VERSION "2.0"

// ============================================================
// FORMULA PROJECT - CAN Communication
// Steering Wheel ↔ ECU
// ============================================================

NS_ :

BS_:
BU_: SteeringWheel ECU

// ============================================================
// MESSAGE: SteeringWheel_Status (TX from SteeringWheel → ECU)
// ============================================================

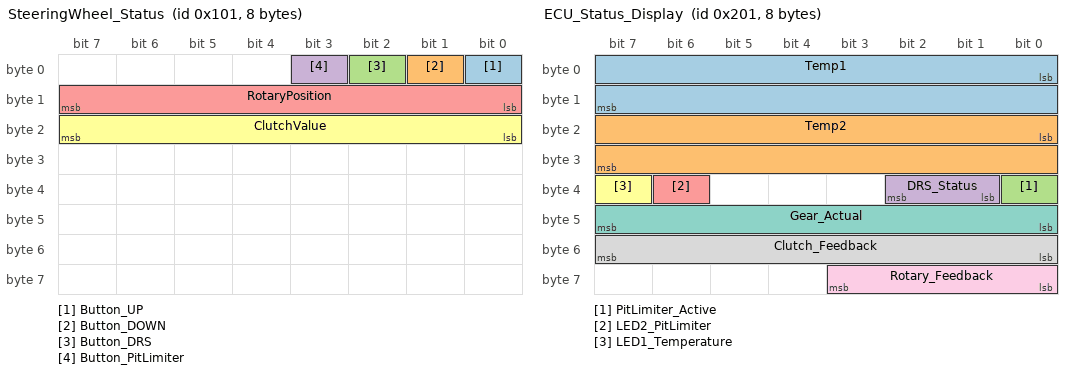
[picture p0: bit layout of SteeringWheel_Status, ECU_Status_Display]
BO_ 257 SteeringWheel_Status: 8 SteeringWheel
 // NOTE: @1+ used for PC simulation (SocketCAN).
 // In target hardware (S32K118 FlexCAN), use @0+.

 SG_ Button_UP :  0|1@1+ (1,0) [0|1] "" ECU
 SG_ Button_DOWN : 1|1@1+ (1,0) [0|1] "" ECU
 SG_ Button_DRS : 2|1@1+ (1,0) [0|1] "" ECU
 SG_ Button_PitLimiter : 3|1@1+ (1,0) [0|1] "" ECU
 SG_ RotaryPosition : 8|8@1+ (1,0) [0|15] ""  ECU
 SG_ ClutchValue : 16|8@1+ (1,0) [0|100] "%"  ECU

// ============================================================
// MESSAGE: ECU_Status_Display (TX from ECU → SteeringWheel)
// ============================================================

BO_ 513 ECU_Status_Display: 8 ECU

 // --- BYTE 0-1 ---
 SG_ Temp1              :  0|16@1+ (0.1,-40) [-40|150] "°C" SteeringWheel

 // --- BYTE 2-3 ---
 SG_ Temp2              : 16|16@1+ (0.1,-40) [-40|150] "°C" SteeringWheel

 // --- BYTE 4 ---
 SG_ PitLimiter_Active  : 32|1@1+ (1,0) [0|1] "" SteeringWheel
 SG_ DRS_Status         : 33|2@1+ (1,0) [0|1] "" SteeringWheel
 SG_ LED2_PitLimiter    : 38|1@1+ (1,0) [0|1] "" SteeringWheel
 SG_ LED1_Temperature   : 39|1@1+ (1,0) [0|1] "" SteeringWheel

 // --- BYTE 5 ---
 SG_ Gear_Actual        : 40|8@1+ (1,0) [0|9] "" SteeringWheel

 // --- BYTE 6 ---
 SG_ Clutch_Feedback    : 48|8@1+ (1,0) [0|100] "%" SteeringWheel

 // --- BYTE 7 ---
 SG_ Rotary_Feedback    : 56|4@1+ (1,0) [0|15] "" SteeringWheel
